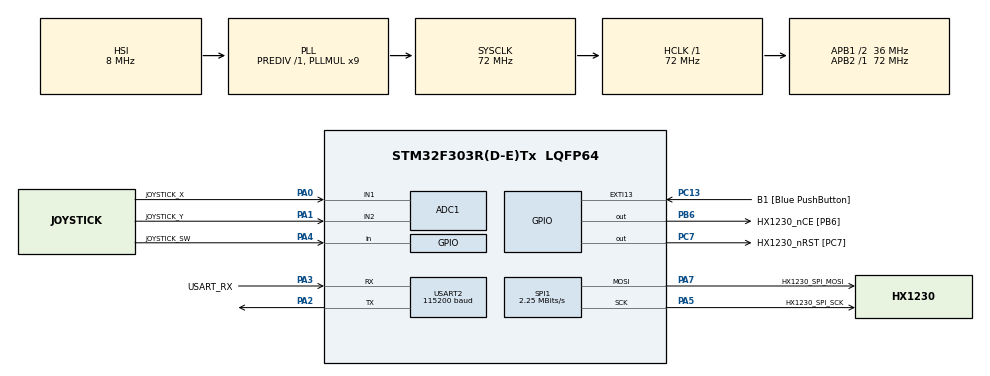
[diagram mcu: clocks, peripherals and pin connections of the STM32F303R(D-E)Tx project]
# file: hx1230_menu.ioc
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ADC1.Channel-0\#ChannelRegularConversion=ADC_CHANNEL_1
ADC1.NbrOfConversionFlag=1
ADC1.Offset-0\#ChannelRegularConversion=0
ADC1.OffsetNumber-0\#ChannelRegularConversion=ADC_OFFSET_NONE
ADC1.Rank-0\#ChannelRegularConversion=1
ADC1.SamplingTime-0\#ChannelRegularConversion=ADC_SAMPLETIME_1CYCLE_5
ADC1.master=1
Mcu.Family=STM32F3
Mcu.Name=STM32F303R(D-E)Tx
Mcu.Package=LQFP64
NVIC.ADC1_2_IRQn=true\:0\:0\:false\:true\:true\:1\:true
NVIC.EXTI15_10_IRQn=true\:0\:0\:false\:true\:true\:2\:true
NVIC.PriorityGroup=NVIC_PRIORITYGROUP_0
NVIC.TIM2_IRQn=true\:0\:0\:false\:false\:true\:true
PA0.GPIO_Label=JOYSTICK_X
PA0.Mode=IN1-Single-Ended
PA0.Signal=ADC1_IN1
PA1.GPIO_Label=JOYSTICK_Y
PA1.Mode=IN2-Single-Ended
PA1.Signal=ADC1_IN2
PA13.GPIO_Label=TMS
PA13.Signal=SYS_JTMS-SWDIO
PA14.GPIO_Label=TCK
PA14.Signal=SYS_JTCK-SWCLK
PA2.Mode=Asynchronous
PA2.Signal=USART2_TX
PA3.GPIO_Label=USART_RX
PA3.GPIO_Mode=GPIO_MODE_AF_PP
PA3.GPIO_PuPd=GPIO_NOPULL
PA3.GPIO_Speed=GPIO_SPEED_FREQ_LOW
PA3.Mode=Asynchronous
PA3.Signal=USART2_RX
PA4.GPIO_Label=JOYSTICK_SW
PA4.GPIO_PuPd=GPIO_PULLUP
PA4.Signal=GPIO_Input
PA5.GPIO_Label=HX1230_SPI_SCK
PA5.Mode=TX_Only_Simplex_Unidirect_Master
PA5.Signal=SPI1_SCK
PA7.GPIO_Label=HX1230_SPI_MOSI
PA7.Mode=TX_Only_Simplex_Unidirect_Master
PA7.Signal=SPI1_MOSI
PB3.GPIO_Label=SWO
PB3.Signal=SYS_JTDO-TRACESWO
PB6.GPIO_Label=HX1230_nCE [PB6]
PB6.Signal=GPIO_Output
PC13.GPIO_Label=B1 [Blue PushButton]
PC13.GPIO_ModeDefaultEXTI=GPIO_MODE_IT_FALLING
PC13.Signal=GPXTI13
PC14-OSC32_IN.Signal=RCC_OSC32_IN
PC15-OSC32_OUT.Signal=RCC_OSC32_OUT
PC7.GPIO_Label=HX1230_nRST [PC7]
PC7.Signal=GPIO_Output
PF0-OSC_IN.Mode=HSE-External-Oscillator
PF0-OSC_IN.Signal=RCC_OSC_IN
PF1-OSC_OUT.Mode=HSE-External-Oscillator
PF1-OSC_OUT.Signal=RCC_OSC_OUT
ProjectManager.HeapSize=0x200
ProjectManager.StackSize=0x400
ProjectManager.TargetToolchain=Other Toolchains (GPDSC)
RCC.AHBFreq_Value=72000000
RCC.APB1CLKDivider=RCC_HCLK_DIV2
RCC.APB1Freq_Value=36000000
RCC.APB1TimFreq_Value=72000000
RCC.APB2Freq_Value=72000000
RCC.APB2TimFreq_Value=72000000
RCC.CortexFreq_Value=72000000
RCC.HCLKFreq_Value=72000000
RCC.HSE_VALUE=8000000
RCC.HSI_VALUE=8000000
RCC.LSE_VALUE=32768
RCC.PLLM=8
RCC.PLLMUL=RCC_PLL_MUL9
RCC.PLLN=336
RCC.PLLP=RCC_PLLP_DIV4
RCC.PLLQ=7
RCC.RCC_PLLsource_Clock_Source_FROM_HSE=RCC_HSE_PREDIV_DIV2
RCC.SYSCLKFreq_VALUE=72000000
RCC.SYSCLKSourceVirtual=RCC_SYSCLKSOURCE_PLLCLK
RCC.USBFreq_Value=72000000
SPI1.BaudRatePrescaler=SPI_BAUDRATEPRESCALER_32
SPI1.CLKPolarity=SPI_POLARITY_LOW
SPI1.CalculateBaudRate=2.25 MBits/s
SPI1.DataSize=SPI_DATASIZE_9BIT
SPI1.Direction=SPI_DIRECTION_2LINES
SPI1.Mode=SPI_MODE_MASTER
SPI1.NSSPMode=SPI_NSS_PULSE_DISABLE
SPI1.VirtualType=VM_MASTER
USART2.BaudRate=115200
USART2.VirtualMode-Asynchronous=VM_ASYNC
USART2.WordLength=WORDLENGTH_8B
VP_TIM2_VS_ClockSourceINT.Mode=Internal
board=NUCLEO-F303RE

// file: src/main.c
/* USER CODE BEGIN Header */
/**
  ******************************************************************************
  * @file           : main.c
  * @brief          : Main program body
  ******************************************************************************
  ** This notice applies to any and all portions of this file
  * that are not between comment pairs USER CODE BEGIN and
  * USER CODE END. Other portions of this file, whether
  * inserted by the user or by software development tools
  * are owned by their respective copyright owners.
  *
  * COPYRIGHT(c) 2020 STMicroelectronics
  *
  * Redistribution and use in source and binary forms, with or without modification,
  * are permitted provided that the following conditions are met:
  *   1. Redistributions of source code must retain the above copyright notice,
  *      this list of conditions and the following disclaimer.
  *   2. Redistributions in binary form must reproduce the above copyright notice,
  *      this list of conditions and the following disclaimer in the documentation
  *      and/or other materials provided with the distribution.
  *   3. Neither the name of STMicroelectronics nor the names of its contributors
  *      may be used to endorse or promote products derived from this software
  *      without specific prior written permission.
  *
  * THIS SOFTWARE IS PROVIDED BY THE COPYRIGHT HOLDERS AND CONTRIBUTORS "AS IS"
  * AND ANY EXPRESS OR IMPLIED WARRANTIES, INCLUDING, BUT NOT LIMITED TO, THE
  * IMPLIED WARRANTIES OF MERCHANTABILITY AND FITNESS FOR A PARTICULAR PURPOSE ARE
  * DISCLAIMED. IN NO EVENT SHALL THE COPYRIGHT HOLDER OR CONTRIBUTORS BE LIABLE
  * FOR ANY DIRECT, INDIRECT, INCIDENTAL, SPECIAL, EXEMPLARY, OR CONSEQUENTIAL
  * DAMAGES (INCLUDING, BUT NOT LIMITED TO, PROCUREMENT OF SUBSTITUTE GOODS OR
  * SERVICES; LOSS OF USE, DATA, OR PROFITS; OR BUSINESS INTERRUPTION) HOWEVER
  * CAUSED AND ON ANY THEORY OF LIABILITY, WHETHER IN CONTRACT, STRICT LIABILITY,
  * OR TORT (INCLUDING NEGLIGENCE OR OTHERWISE) ARISING IN ANY WAY OUT OF THE USE
  * OF THIS SOFTWARE, EVEN IF ADVISED OF THE POSSIBILITY OF SUCH DAMAGE.
  *
  ******************************************************************************
  */
/* USER CODE END Header */

#include "main.h"
#include "adc.h"
#include "spi.h"
#include "tim.h"
#include "usart.h"
#include "gpio.h"

/* USER CODE BEGIN Includes */
#include "app.h"
/* USER CODE END Includes */

/* USER CODE BEGIN PV */
/* Private variables ---------------------------------------------------------*/

/* USER CODE END PV */

void SystemClock_Config(void);
static void MX_NVIC_Init(void);
/* USER CODE BEGIN PFP */
/* Private function prototypes -----------------------------------------------*/

/* USER CODE END PFP */

int main(void)
{

  /* MCU Configuration--------------------------------------------------------*/

  /* Reset of all peripherals, Initializes the Flash interface and the Systick. */
  HAL_Init();

  /* Configure the system clock */
  SystemClock_Config();

  /* Initialize all configured peripherals */
  MX_GPIO_Init();
  MX_SPI1_Init();
  MX_ADC1_Init();
  MX_USART2_UART_Init();
  MX_TIM2_Init();

  /* Initialize interrupts */
  MX_NVIC_Init();

  /* Infinite loop */
  while (1)
  {

    /* USER CODE BEGIN 3 */
    app_start();
  }
  /* USER CODE END 3 */
}

void SystemClock_Config(void)
{
  RCC_OscInitTypeDef RCC_OscInitStruct = {0};
  RCC_ClkInitTypeDef RCC_ClkInitStruct = {0};
  RCC_PeriphCLKInitTypeDef PeriphClkInit = {0};

  /**Initializes the CPU, AHB and APB busses clocks
  */
  RCC_OscInitStruct.OscillatorType = RCC_OSCILLATORTYPE_HSI;
  RCC_OscInitStruct.HSIState = RCC_HSI_ON;
  RCC_OscInitStruct.HSICalibrationValue = RCC_HSICALIBRATION_DEFAULT;
  RCC_OscInitStruct.PLL.PLLState = RCC_PLL_ON;
  RCC_OscInitStruct.PLL.PLLSource = RCC_PLLSOURCE_HSI;
  RCC_OscInitStruct.PLL.PLLMUL = RCC_PLL_MUL9;
  RCC_OscInitStruct.PLL.PREDIV = RCC_PREDIV_DIV1;
  if (HAL_RCC_OscConfig(&RCC_OscInitStruct) != HAL_OK)
  {
    Error_Handler();
  }
  /**Initializes the CPU, AHB and APB busses clocks
  */
  RCC_ClkInitStruct.ClockType = RCC_CLOCKTYPE_HCLK|RCC_CLOCKTYPE_SYSCLK
                              |RCC_CLOCKTYPE_PCLK1|RCC_CLOCKTYPE_PCLK2;
  RCC_ClkInitStruct.SYSCLKSource = RCC_SYSCLKSOURCE_PLLCLK;
  RCC_ClkInitStruct.AHBCLKDivider = RCC_SYSCLK_DIV1;
  RCC_ClkInitStruct.APB1CLKDivider = RCC_HCLK_DIV2;
  RCC_ClkInitStruct.APB2CLKDivider = RCC_HCLK_DIV1;

  if (HAL_RCC_ClockConfig(&RCC_ClkInitStruct, FLASH_LATENCY_2) != HAL_OK)
  {
    Error_Handler();
  }
  PeriphClkInit.PeriphClockSelection = RCC_PERIPHCLK_USART2|RCC_PERIPHCLK_ADC12
                              |RCC_PERIPHCLK_TIM2;
  PeriphClkInit.Usart2ClockSelection = RCC_USART2CLKSOURCE_PCLK1;
  PeriphClkInit.Adc12ClockSelection = RCC_ADC12PLLCLK_DIV1;
  PeriphClkInit.Tim2ClockSelection = RCC_TIM2CLK_HCLK;
  if (HAL_RCCEx_PeriphCLKConfig(&PeriphClkInit) != HAL_OK)
  {
    Error_Handler();
  }
}

/**
  * @brief NVIC Configuration.
  * @retval None
  */
static void MX_NVIC_Init(void)
{
  /* ADC1_2_IRQn interrupt configuration */
  HAL_NVIC_SetPriority(ADC1_2_IRQn, 0, 0);
  HAL_NVIC_EnableIRQ(ADC1_2_IRQn);
  /* EXTI15_10_IRQn interrupt configuration */
  HAL_NVIC_SetPriority(EXTI15_10_IRQn, 0, 0);
  HAL_NVIC_EnableIRQ(EXTI15_10_IRQn);
}

void Error_Handler(void)
{
  while(1)
  {
  }
}

/************************ (C) COPYRIGHT STMicroelectronics *****END OF FILE****/
